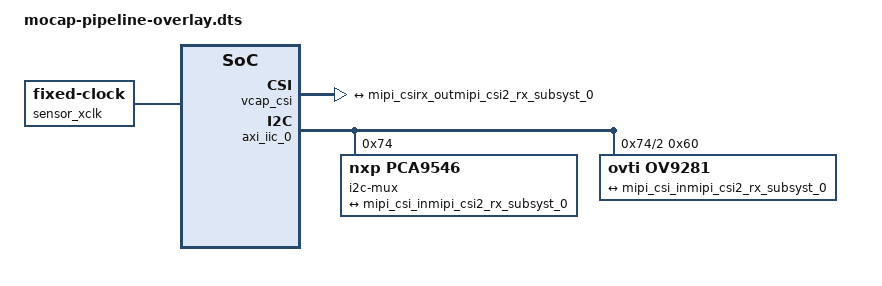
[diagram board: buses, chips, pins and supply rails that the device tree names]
/dts-v1/;
/plugin/;

/*
 * mocap-pipeline-overlay.dts — OV9281 MIPI capture pipeline as a single
 * self-contained device-tree overlay.
 *
 *   OV9281 --I2C(TCA9546A ch2)--> [config]
 *   OV9281 --MIPI CSI-2--> mipi_csi2_rx_subsystem --AXIS--> AXI VDMA S2MM --> DDR
 *
 * The isp_math_wrapper is intentionally LEFT OUT of this media graph. Reach it
 * directly via /dev/mem at 0xA0011000 for now; it rejoins the pipeline later
 * once it grows its own AXIS in/out ports.
 *
 * --- Why /include/ "pl.dtsi" ---
 * pl.dtsi is the Xilinx-autogenerated PL description (the same source that gets
 * compiled standalone into pl.dtbo). It carries its own /dts-v1/; /plugin/;.
 * By pulling it into THIS compilation unit, every PL label (axi_iic_0,
 * axi_vdma_0, the mipi_csi endpoints, ...) resolves at COMPILE time, so this
 * overlay needs no apply-time symbol lookup against a previously-loaded
 * pl.dtbo. Load THIS .dtbo (not pl.dtbo) with fpgautil and you get bitstream +
 * full pipeline in one shot. pl.dtsi itself is never edited.
 *
 * The dtc include path already contains the plnx_workspace device-tree dir
 * (see the device-tree recipe), so the bare filename resolves at build time.
 */
/include/ "pl.dtsi"

/* New root-level nodes are added by targeting the root via the &{/} path-ref. */
&{/} {
	/* Dummy 24 MHz clock for the OV9281.
	 * The camera module generates its own XCLK in hardware, so nothing here
	 * physically drives the sensor. But this kernel's ov9282.c uses
	 * devm_clk_get() (mandatory, not _optional), rejects any rate !=
	 * OV9282_INCLK_RATE (24 MHz), then clk_prepare_enable()s it. This
	 * fixed-clock satisfies all three with a no-op provider. Do NOT delete
	 * it — without it probe fails with "could not get inclk". */
	sensor_xclk: sensor-xclk {
		compatible = "fixed-clock";
		#clock-cells = <0>;
		clock-frequency = <24000000>;
	};

	/* Xilinx V4L2 capture sink (xilinx-vipp). */
	vcap_csi: vcap_csi {
		compatible = "xlnx,video";
		dmas = <&axi_vdma_0 1>;	/* S2MM (write) channel. If the vipp probe
					 * reports "no channel", try 0 — this VDMA
					 * only instantiates the S2MM channel. */
		dma-names = "port0";

		ports {
			#address-cells = <1>;
			#size-cells = <0>;

			port@0 {
				reg = <0>;
				direction = "input";
				vcap_in: endpoint {
					remote-endpoint = <&mipi_csirx_outmipi_csi2_rx_subsyst_0>;
				};
			};
		};
	};
};

/* ---- Camera on the muxed I2C bus ------------------------------------ */
&axi_iic_0 {
	#address-cells = <1>;
	#size-cells = <0>;

	/* TCA9546A 4-channel I2C switch; OV9281 sits on channel 2 — matches the
	 * bare-metal TCA9546_PORT2_EN routing in vitis/.../main.cc. If the camera
	 * is wired straight to axi_iic (no mux) on your board rev, delete this
	 * i2c-mux node and move sensor@60 directly under &axi_iic_0. */
	i2c-mux@74 {
		compatible = "nxp,pca9546";
		reg = <0x74>;
		#address-cells = <1>;
		#size-cells = <0>;

		i2c@2 {
			reg = <2>;
			#address-cells = <1>;
			#size-cells = <0>;

			ov9281: sensor@60 {
				/* This kernel's ov9282.c of_match_table matches both
				 * "ovti,ov9281" and "ovti,ov9282" (verified in build
				 * tree). Use ov9281 to reflect the actual silicon. */
				compatible = "ovti,ov9281";
				reg = <0x60>;
				clocks = <&sensor_xclk>;
				clock-names = "inclk";
				/* reset-gpios = <...>;  optional; wire to TCA6408A / MIO if used */

				port {
					ov9281_out: endpoint {
						remote-endpoint = <&mipi_csi_inmipi_csi2_rx_subsyst_0>;
						data-lanes = <1 2>;
						link-frequencies = /bits/ 64 <400000000>;  /* verify vs driver mode */
					};
				};
			};
		};
	};
};

/* ---- Wire CSI-2 RX input (port@0) to the sensor --------------------- */
&mipi_csi_inmipi_csi2_rx_subsyst_0 {
	/* pl.dtsi left this dangling ("User need to add remote-endpoint"). */
	remote-endpoint = <&ov9281_out>;
};

/* ---- Re-point CSI-2 RX output (port@1): ISP wrapper -> VDMA sink ----- */
&mipi_csirx_outmipi_csi2_rx_subsyst_0 {
	/* pl.dtsi pointed this at &isp_math_wrapper_0... (a label never defined
	 * -> unresolved phandle). Override it to feed the VDMA capture node
	 * directly, cutting the ISP wrapper out of the media graph entirely. */
	remote-endpoint = <&vcap_in>;
};
